# FT32F0xx register map
File version: 1.0
Registers are 32-bit, read-write, reset 0x0 unless marked. A register's access mark holds for its fields unless they carry their own. Offsets are from the block's base; [hi:lo] are bit positions; {n}, {i} and the like mark numbered series.

## LEB — LEB and FLT support
Base 0x4000FC00
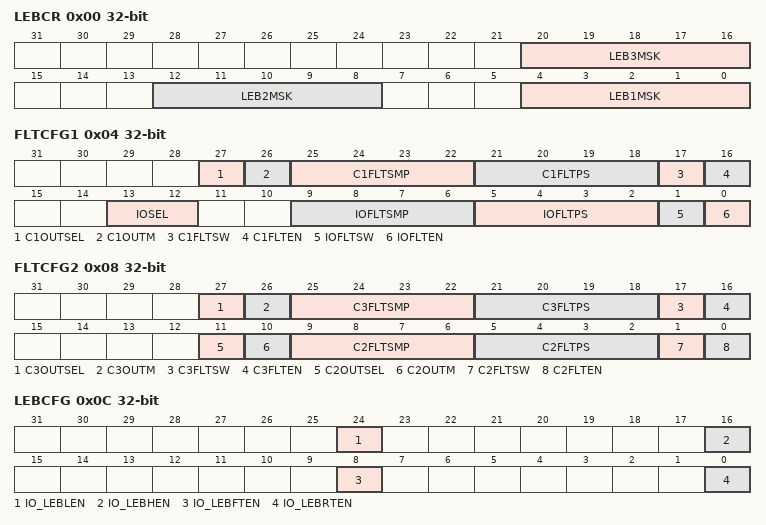
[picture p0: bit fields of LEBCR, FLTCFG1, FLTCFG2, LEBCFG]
0x00 LEBCR
  [20:16] LEB3MSK — LEB3MSK Identifier
  [12:8] LEB2MSK — LEB2MSK Identifier
  [4:0] LEB1MSK — LEB1MSK Identifier
0x04 FLTCFG1
  [27] C1OUTSEL — C1OUTSEL Identifier
  [26] C1OUTM — C1OUTM Identifier
  [25:22] C1FLTSMP — C1FLTSMP Identifier
  [21:18] C1FLTPS — C1FLTPS Identifier
  [17] C1FLTSW — C1FLTSW Identifier
  [16] C1FLTEN — C1FLTEN Identifier
  [13:12] IOSEL — IOSEL Identifier
  [9:6] IOFLTSMP — IOFLTSMP Identifier
  [5:2] IOFLTPS — IOFLTPS Identifier
  [1] IOFLTSW — IOFLTSW Identifier
  [0] IOFLTEN — IOFLTEN Identifier
0x08 FLTCFG2
  [27] C3OUTSEL — C3OUTSEL Identifier
  [26] C3OUTM — C3OUTM Identifier
  [25:22] C3FLTSMP — C3FLTSMP Identifier
  [21:18] C3FLTPS — C3FLTPS Identifier
  [17] C3FLTSW — C3FLTSW Identifier
  [16] C3FLTEN — C3FLTEN Identifier
  [11] C2OUTSEL — C2OUTSEL Identifier
  [10] C2OUTM — C2OUTM Identifier
  [9:6] C2FLTSMP — C2FLTSMP Identifier
  [5:2] C2FLTPS — C2FLTPS Identifier
  [1] C2FLTSW — C2FLTSW Identifier
  [0] C2FLTEN — C2FLTEN Identifier
0x0C LEBCFG
  [24] IO_LEBLEN — IO_LEBLEN Identifier
  [16] IO_LEBHEN — IO_LEBHEN Identifier
  [8] IO_LEBFTEN — IO_LEBFTEN Identifier
  [0] IO_LEBRTEN — IO_LEBRTEN Identifier
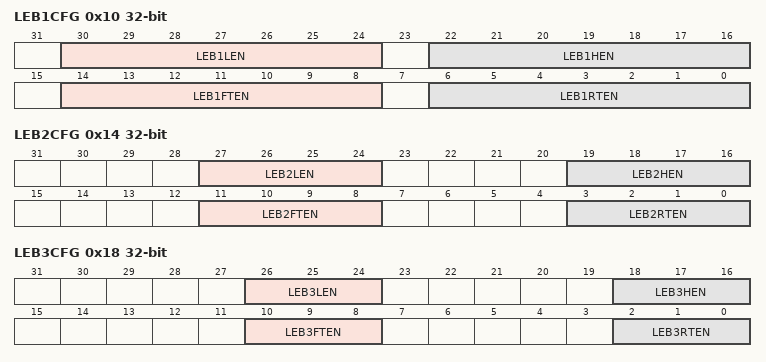
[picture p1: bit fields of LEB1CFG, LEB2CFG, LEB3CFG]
0x10 LEB1CFG
  [30:24] LEB1LEN — LEB1LEN Identifier
  [22:16] LEB1HEN — LEB1HEN Identifier
  [14:8] LEB1FTEN — LEB1FTEN Identifier
  [6:0] LEB1RTEN — LEB1RTEN Identifier
0x14 LEB2CFG
  [27:24] LEB2LEN — LEB2LEN Identifier
  [19:16] LEB2HEN — LEB2HEN Identifier
  [11:8] LEB2FTEN — LEB2FTEN Identifier
  [3:0] LEB2RTEN — LEB2RTEN Identifier
0x18 LEB3CFG
  [26:24] LEB3LEN — LEB3LEN Identifier
  [18:16] LEB3HEN — LEB3HEN Identifier
  [10:8] LEB3FTEN — LEB3FTEN Identifier
  [2:0] LEB3RTEN — LEB3RTEN Identifier
{0x18+4i} LEB{i}PR (i=1..3)
  [9:0] LEB{i}PR — LEB{i}PR Identifier

## USB — Universal serial bus full-speed device interface
Base 0x40005C00
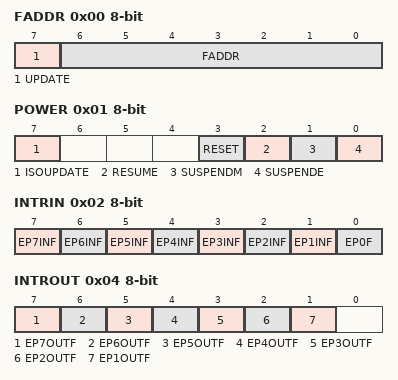
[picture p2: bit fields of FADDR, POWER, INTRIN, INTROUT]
0x00 FADDR 8-bit
  [7] UPDATE — Endpoint address
  [6:0] FADDR — Status bits, for transmission transfers
0x01 POWER 8-bit
  [7] ISOUPDATE
  [3] RESET — Status bits, for transmission transfers
  [2] RESUME — Data Toggle, for transmission transfers
  [1] SUSPENDM — Correct Transfer for transmission
  [0] SUSPENDE — Endpoint kind
0x02 INTRIN 8-bit
  [7] EP7INF — Endpoint address
  [6] EP6INF — Status bits, for transmission transfers
  [5] EP5INF — Data Toggle, for transmission transfers
  [4] EP4INF — Correct Transfer for transmission
  [3] EP3INF — Endpoint kind
  [2] EP2INF — Endpoint type
  [1] EP1INF — Setup transaction completed
  [0] EP0F — Status bits, for reception transfers
0x04 INTROUT 8-bit
  [7] EP7OUTF — Endpoint address
  [6] EP6OUTF — Status bits, for transmission transfers
  [5] EP5OUTF — Data Toggle, for transmission transfers
  [4] EP4OUTF — Correct Transfer for transmission
  [3] EP3OUTF — Endpoint kind
  [2] EP2OUTF — Endpoint type
  [1] EP1OUTF — Setup transaction completed
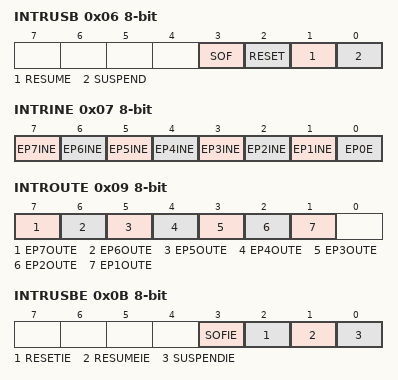
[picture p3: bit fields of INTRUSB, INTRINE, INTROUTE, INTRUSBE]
0x06 INTRUSB 8-bit
  [3] SOF — Endpoint kind
  [2] RESET — Endpoint type
  [1] RESUME — Setup transaction completed
  [0] SUSPEND — Status bits, for reception transfers
0x07 INTRINE 8-bit
  [7] EP7INE — Endpoint kind
  [6] EP6INE — Endpoint type
  [5] EP5INE — Setup transaction completed
  [4] EP4INE — Status bits, for reception transfers
  [3] EP3INE — Endpoint kind
  [2] EP2INE — Endpoint type
  [1] EP1INE — Setup transaction completed
  [0] EP0E — Status bits, for reception transfers
0x09 INTROUTE 8-bit
  [7] EP7OUTE — Endpoint kind
  [6] EP6OUTE — Endpoint type
  [5] EP5OUTE — Setup transaction completed
  [4] EP4OUTE — Status bits, for reception transfers
  [3] EP3OUTE — Endpoint kind
  [2] EP2OUTE — Endpoint type
  [1] EP1OUTE — Setup transaction completed
0x0B INTRUSBE 8-bit
  [3] SOFIE — Endpoint kind
  [2] RESETIE — Endpoint type
  [1] RESUMEIE — Setup transaction completed
  [0] SUSPENDIE — Setup transaction completed
0x0C FRAM1 8-bit
  [7:0] FRAM1 — Force USB Reset
0x0D FRAM2 8-bit access not given
  [2:0] FRAM2 — Force USB Reset
0x0E INDEX 8-bit access not given
  [3:0] INDEX — Force USB Reset
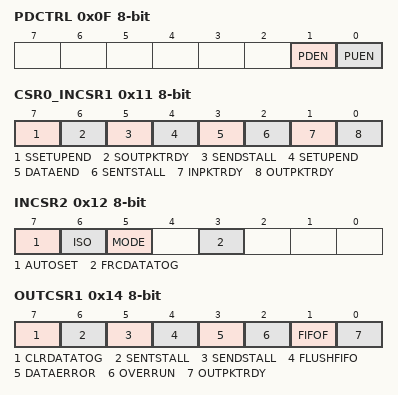
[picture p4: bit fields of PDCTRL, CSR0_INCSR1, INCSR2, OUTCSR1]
0x0F PDCTRL 8-bit access not given
  [1] PDEN — Force USB Reset
  [0] PUEN — Force USB Reset
0x10 INMAXP 8-bit access not given
  [7:0] INMAXP — Force USB Reset
0x11 CSR0_INCSR1 8-bit access not given
  [7] SSETUPEND — Endpoint kind
  [6] SOUTPKTRDY — Endpoint type
  [5] SENDSTALL — Setup transaction completed
  [4] SETUPEND — Status bits, for reception transfers
  [3] DATAEND — Endpoint kind
  [2] SENTSTALL — Endpoint type
  [1] INPKTRDY — Setup transaction completed
  [0] OUTPKTRDY — Setup transaction completed
0x12 INCSR2 8-bit access not given
  [7] AUTOSET — Endpoint kind
  [6] ISO — Endpoint type
  [5] MODE — Setup transaction completed
  [3] FRCDATATOG — Endpoint kind
0x13 OUTMAXP 8-bit access not given
  [7:0] OUTMAXP — Endpoint kind
0x14 OUTCSR1 8-bit access not given
  [7] CLRDATATOG — Endpoint kind
  [6] SENTSTALL — Endpoint type
  [5] SENDSTALL — Setup transaction completed
  [4] FLUSHFIFO — Status bits, for reception transfers
  [3] DATAERROR — Endpoint kind
  [2] OVERRUN — Endpoint type
  [1] FIFOF — Setup transaction completed
  [0] OUTPKTRDY — Setup transaction completed
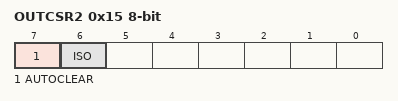
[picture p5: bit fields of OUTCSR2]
0x15 OUTCSR2 8-bit access not given
  [7] AUTOCLEAR — Endpoint kind
  [6] ISO — Endpoint type
0x16 OUTCOUNTER 8-bit access not given
  [7:0] OUTCOUNTER — Endpoint kind
{0x20+4i} FIFO{i} 8-bit access not given (i=0..7)
  [7:0] FIFO{i} — Endpoint kind

## DIV — DIV support
Base 0x40010080
0x00 DIV_DID
  [30:0] DID — Device Identifier
0x04 DIV_DIS
  [15:0] DIS — Device Identifier
0x08 DIV_QUO ro
  [30:0] QUO — Device Identifier
0x0C DIV_REM ro
  [15:0] REM — Device Identifier
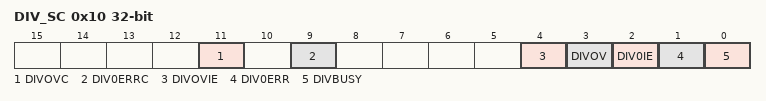
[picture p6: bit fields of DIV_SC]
0x10 DIV_SC access per field
  [11] DIVOVC ro — Device Identifier
  [9] DIV0ERRC ro — Device Identifier
  [4] DIVOVIE rw — Device Identifier
  [3] DIVOV ro — Device Identifier
  [2] DIV0IE rw — Device Identifier
  [1] DIV0ERR ro — Device Identifier
  [0] DIVBUSY ro — Device Identifier
